# MDR32FG16S1QI register map
Vendor: Milandr; File version: 1.0
CPU: CM3 r1p1, little endian, no MPU, no FPU, 3 interrupt priority bits
Registers are 32-bit, read-write, reset 0x0 unless marked. A register's access mark holds for its fields unless they carry their own. Offsets are from the block's base; [hi:lo] are bit positions; {n}, {i} and the like mark numbered series.

## MDR_SSP1 — SSP1 interfase controller registers
Base 0x40040000; register names take the prefix MDR_SSP1_
Same registers: MDR_SSP3 0x40000000 (register names take the prefix MDR_SSP3_), MDR_SSP4 0x40008000 (register names take the prefix MDR_SSP4_), MDR_SSP2 0x400A0000 (register names take the prefix MDR_SSP2_)
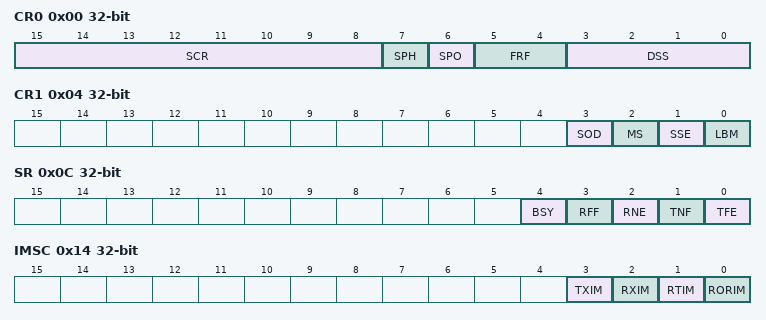
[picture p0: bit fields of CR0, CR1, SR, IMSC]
0x00 CR0 — SSP Control0 Register
  [15:8] SCR, [7] SPH, [6] SPO, [5:4] FRF, [3:0] DSS
0x04 CR1 — SSP Control1 Register
  [3] SOD, [2] MS, [1] SSE, [0] LBM
0x08 DR — SSP Data Register
  [15:0] DATA
0x0C SR — SSP Status Register
  [4] BSY, [3] RFF, [2] RNE, [1] TNF, [0] TFE
0x10 CPSR — SSP Clock Prescaler Register
  [7:0] CPSDVSR
0x14 IMSC — SSP Interrupt Mask Register
  [3] TXIM, [2] RXIM, [1] RTIM, [0] RORIM
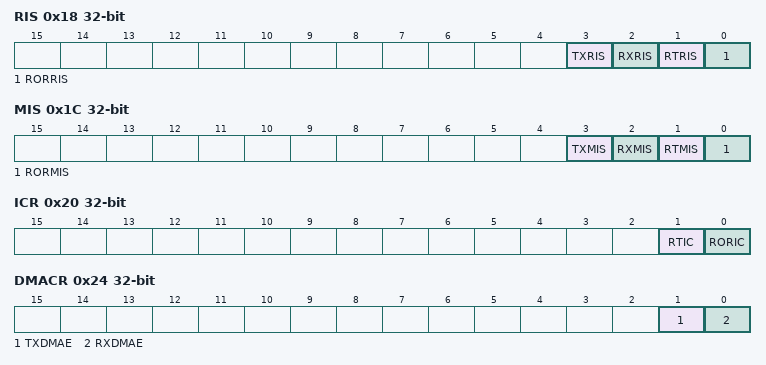
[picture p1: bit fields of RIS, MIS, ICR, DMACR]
0x18 RIS — SSP Interrupt Pending Register
  [3] TXRIS, [2] RXRIS, [1] RTRIS, [0] RORRIS
0x1C MIS — SSP Masked Interrupt Pending Register
  [3] TXMIS, [2] RXMIS, [1] RTMIS, [0] RORMIS
0x20 ICR — SSP Interrupt Clear Register
  [1] RTIC, [0] RORIC
0x24 DMACR — SSP DMA Control Register
  [1] TXDMAE, [0] RXDMAE

## MDR_SDIO — SDIO Controller
Base 0x40048000; register names take the prefix MDR_SDIO_
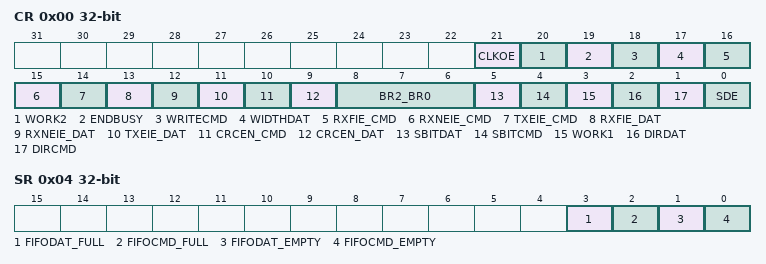
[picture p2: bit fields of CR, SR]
0x00 CR — SDIO Control Register
  [21] CLKOE, [20] WORK2, [19] ENDBUSY, [18] WRITECMD, [17] WIDTHDAT, [16] RXFIE_CMD, [15] RXNEIE_CMD, [14] TXEIE_CMD, [13] RXFIE_DAT, [12] RXNEIE_DAT, [11] TXEIE_DAT, [10] CRCEN_CMD, [9] CRCEN_DAT, [8:6] BR2_BR0, [5] SBITDAT, [4] SBITCMD, [3] WORK1, [2] DIRDAT, [1] DIRCMD, [0] SDE
0x04 SR — SDIO Status Register
  [3] FIFODAT_FULL, [2] FIFOCMD_FULL, [1] FIFODAT_EMPTY, [0] FIFOCMD_EMPTY
0x08 CMDDR — SDIO Command Data Register
  [31:0] RX_FIFO_TX_FIFO
0x0C DATDR — SDIO Data Register
  [31:0] RX_FIFO_TX_FIFO
0x10 CMDCRC — SDIO Command CRC Register
  [6:0] CMDCRC
{0x14+4i} DAT{i}CRC (i=0..3) — SDIO Data{i} CRC Register
  [15:0] DAT{i}CRC
0x24 CMDTransfer — SDIO Command Transfer Register
  [15:0] CMDtransfer
0x28 DATtransfer — SDIO Data Transfer Register
  [15:0] DATtransfer

## MDR_I2C — I2C interfase controller registers
Base 0x40050000; register names take the prefix MDR_I2C_
0x00 PRL — I2C Prescaler (low byte) Register
  [7:0] PR
0x04 PRH — I2C Prescaler (high byte) Register
  [7:0] PR
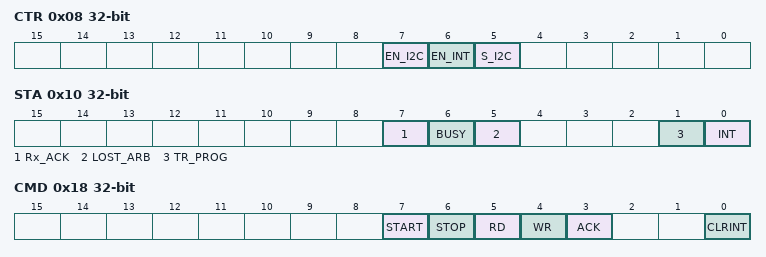
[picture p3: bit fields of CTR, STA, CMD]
0x08 CTR — I2C Control Register
  [7] EN_I2C, [6] EN_INT, [5] S_I2C
0x0C RXD — I2C Received Data Register
  [7:0] RXD
0x10 STA — I2C Status Register
  [7] Rx_ACK, [6] BUSY, [5] LOST_ARB, [1] TR_PROG, [0] INT
0x14 TXD — I2C Transmitted Data Register
  [7:0] TXD
0x18 CMD — I2C Command Register
  [7] START, [6] STOP, [5] RD, [4] WR, [3] ACK, [0] CLRINT

## MDR_POWER — POWER
Base 0x40058000; register names take the prefix MDR_POWER_
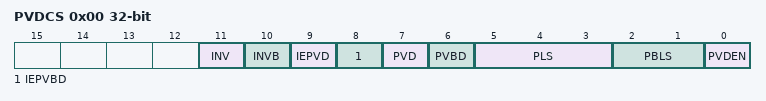
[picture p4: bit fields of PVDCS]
0x00 PVDCS — POWER Power Detector Control/Status Register
  [11] INV, [10] INVB, [9] IEPVD, [8] IEPVBD, [7] PVD, [6] PVBD, [5:3] PLS, [2:1] PBLS, [0] PVDEN

## MDR_WWDG — WWDT
Base 0x40060000; register names take the prefix MDR_WWDG_
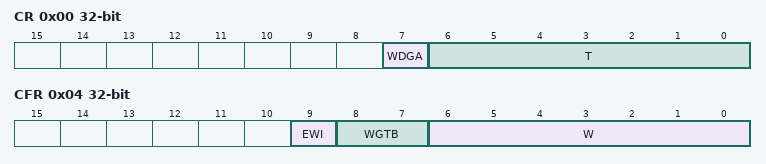
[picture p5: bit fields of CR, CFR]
0x00 CR — WWDG Command Register
  [7] WDGA, [6:0] T
0x04 CFR — WWDG Configuration Register
  [9] EWI, [8:7] WGTB, [6:0] W
0x08 SR — WWDG Status Register
  [0] EWIF

## MDR_IWDG — IWDT
Base 0x40068000; register names take the prefix MDR_IWDG_
0x00 KR — IWDG Key Register
  [15:0] KEY
0x04 PR — IWDG Clock Prescaler Register
  [2:0] PR
0x08 RLR — IWDG Reload Register
  [11:0] RLR
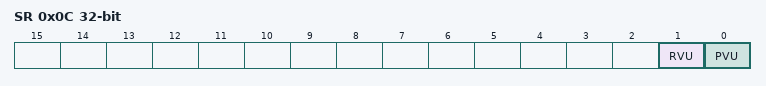
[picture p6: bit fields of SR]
0x0C SR — IWDG Status Register
  [1] RVU, [0] PVU

## MDR_TIMER1 — TIMER1
Base 0x40070000; register names take the prefix MDR_TIMER1_
Same registers: MDR_TIMER2 0x40078000 (register names take the prefix MDR_TIMER2_), MDR_TIMER3 0x40080000 (register names take the prefix MDR_TIMER3_)
0x00 CNT — Timer Counter Register
  [15:0] CNT
0x04 PSG — Timer Clock Prescaler Register
  [15:0] PSG
0x08 ARR — Timer Auto-Reload Register
  [15:0] ARR
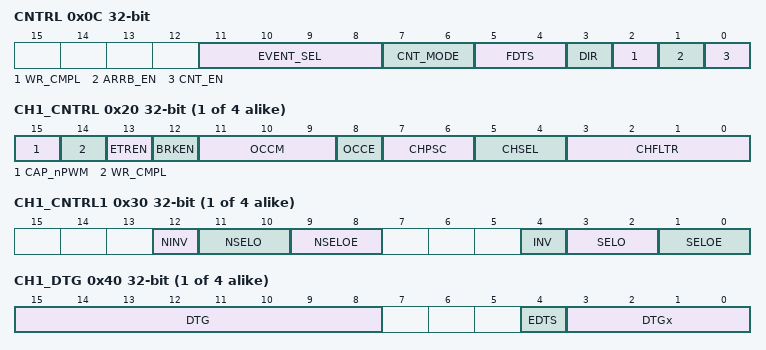
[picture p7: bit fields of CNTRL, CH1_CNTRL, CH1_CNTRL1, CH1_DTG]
0x0C CNTRL — Timer Control Register
  [11:8] EVENT_SEL, [7:6] CNT_MODE, [5:4] FDTS, [3] DIR, [2] WR_CMPL, [1] ARRB_EN, [0] CNT_EN
{0xC+4i} CCR{i} (i=1..4) — Timer Capture/Compare Register
  [15:0] CCR
{0x1C+4i} CH{i}_CNTRL (i=1..4) — Timer Channel Control Register
  [15] CAP_nPWM, [14] WR_CMPL, [13] ETREN, [12] BRKEN, [11:9] OCCM, [8] OCCE, [7:6] CHPSC, [5:4] CHSEL, [3:0] CHFLTR
{0x2C+4i} CH{i}_CNTRL1 (i=1..4) — Timer Channel Control1 Register
  [12] NINV, [11:10] NSELO, [9:8] NSELOE, [4] INV, [3:2] SELO, [1:0] SELOE
{0x3C+4i} CH{i}_DTG (i=1..4) — Timer Channel DTG Register
  [15:8] DTG, [4] EDTS, [3:0] DTGx
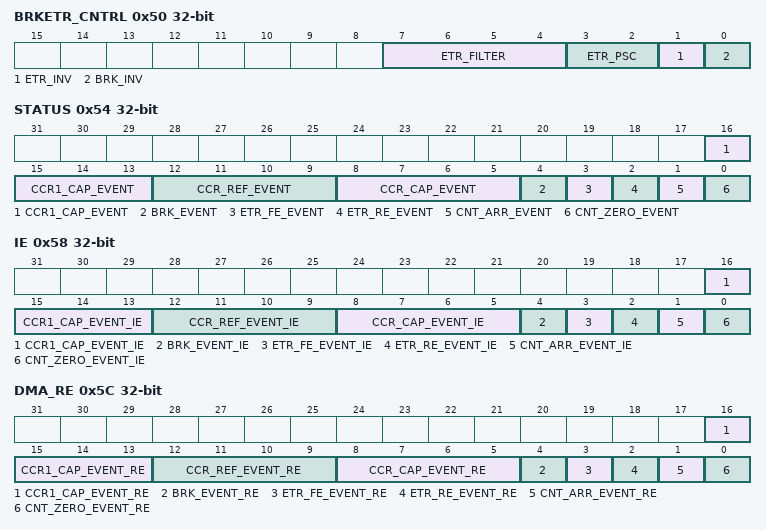
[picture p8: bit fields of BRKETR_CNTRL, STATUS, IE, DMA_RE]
0x50 BRKETR_CNTRL — Timer BRK/ETR Control Register
  [7:4] ETR_FILTER, [3:2] ETR_PSC, [1] ETR_INV, [0] BRK_INV
0x54 STATUS — Timer Status Register
  [16:13] CCR1_CAP_EVENT, [12:9] CCR_REF_EVENT, [8:5] CCR_CAP_EVENT, [4] BRK_EVENT, [3] ETR_FE_EVENT, [2] ETR_RE_EVENT, [1] CNT_ARR_EVENT, [0] CNT_ZERO_EVENT
0x58 IE — Timer Interrupt Enable Register
  [16:13] CCR1_CAP_EVENT_IE, [12:9] CCR_REF_EVENT_IE, [8:5] CCR_CAP_EVENT_IE, [4] BRK_EVENT_IE, [3] ETR_FE_EVENT_IE, [2] ETR_RE_EVENT_IE, [1] CNT_ARR_EVENT_IE, [0] CNT_ZERO_EVENT_IE
0x5C DMA_RE — Timer DMA Request Enable Register
  [16:13] CCR1_CAP_EVENT_RE, [12:9] CCR_REF_EVENT_RE, [8:5] CCR_CAP_EVENT_RE, [4] BRK_EVENT_RE, [3] ETR_FE_EVENT_RE, [2] ETR_RE_EVENT_RE, [1] CNT_ARR_EVENT_RE, [0] CNT_ZERO_EVENT_RE
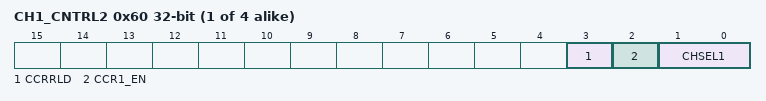
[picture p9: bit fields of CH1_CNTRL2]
{0x5C+4i} CH{i}_CNTRL2 (i=1..4) — Timer Channel Control2 Register
  [3] CCRRLD, [2] CCR1_EN, [1:0] CHSEL1
0x70 CCR11 — Timer Capture/Compare1 Register
  [15:0] CCR
0x74 CCR21 — Timer Capture/Compare1 Register
  [15:0] CCR
0x78 CCR31 — Timer Capture/Compare1 Register
  [15:0] CCR
0x7C CCR41 — Timer Capture/Compare1 Register
  [15:0] CCR
